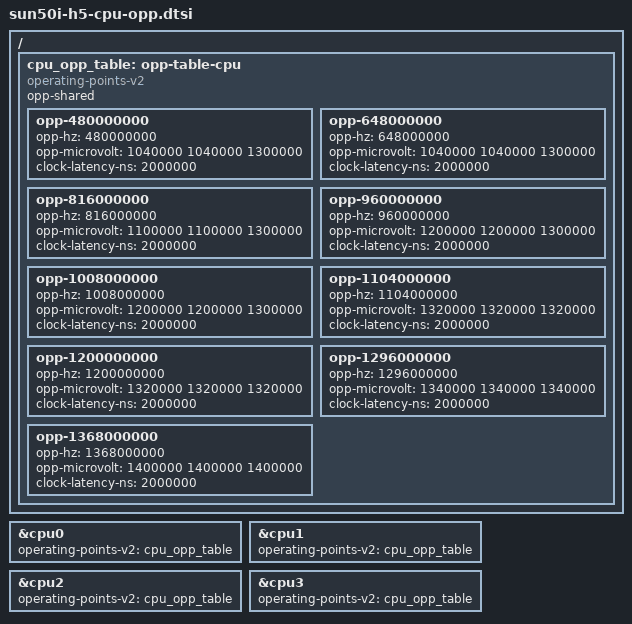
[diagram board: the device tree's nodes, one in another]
// SPDX-License-Identifier: (GPL-2.0+ OR MIT)
// Copyright (C) 2020 Chen-Yu Tsai <wens@csie.org>

/ {
	cpu_opp_table: opp-table-cpu {
		compatible = "operating-points-v2";
		opp-shared;

		opp-480000000 {
			opp-hz = /bits/ 64 <480000000>;
			opp-microvolt = <1040000 1040000 1300000>;
			clock-latency-ns = <2000000>;
		};

		opp-648000000 {
			opp-hz = /bits/ 64 <648000000>;
			opp-microvolt = <1040000 1040000 1300000>;
			clock-latency-ns = <2000000>;
		};

		opp-816000000 {
			opp-hz = /bits/ 64 <816000000>;
			opp-microvolt = <1100000 1100000 1300000>;
			clock-latency-ns = <2000000>;
		};

		opp-960000000 {
			opp-hz = /bits/ 64 <960000000>;
			opp-microvolt = <1200000 1200000 1300000>;
			clock-latency-ns = <2000000>;
		};

		opp-1008000000 {
			opp-hz = /bits/ 64 <1008000000>;
			opp-microvolt = <1200000 1200000 1300000>;
			clock-latency-ns = <2000000>;
		};

		opp-1104000000 {
			opp-hz = /bits/ 64 <1104000000>;
			opp-microvolt = <1320000 1320000 1320000>;
			clock-latency-ns = <2000000>;
		};

		opp-1200000000 {
			opp-hz = /bits/ 64 <1200000000>;
			opp-microvolt = <1320000 1320000 1320000>;
			clock-latency-ns = <2000000>;
		};

		opp-1296000000 {
			opp-hz = /bits/ 64 <1296000000>;
			opp-microvolt = <1340000 1340000 1340000>;
			clock-latency-ns = <2000000>;
		};

		opp-1368000000 {
			opp-hz = /bits/ 64 <1368000000>;
			opp-microvolt = <1400000 1400000 1400000>;
			clock-latency-ns = <2000000>;
		};
	};
};

&cpu0 {
	operating-points-v2 = <&cpu_opp_table>;
};

&cpu1 {
	operating-points-v2 = <&cpu_opp_table>;
};

&cpu2 {
	operating-points-v2 = <&cpu_opp_table>;
};

&cpu3 {
	operating-points-v2 = <&cpu_opp_table>;
};
